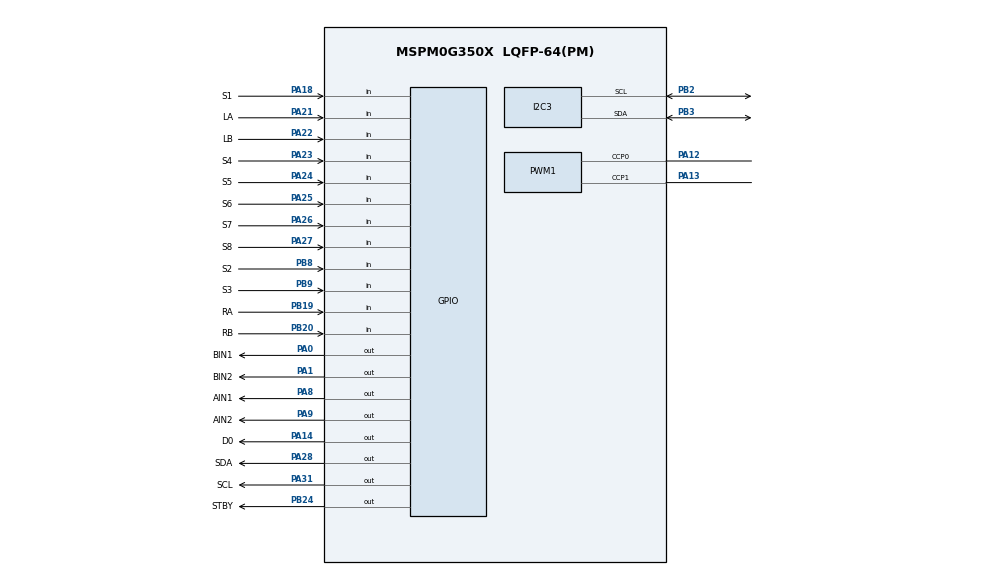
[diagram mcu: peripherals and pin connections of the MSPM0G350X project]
/**
 * @cliArgs --device "MSPM0G350X" --part "Default" --package "LQFP-64(PM)" --product "mspm0_sdk@2.10.00.04"
 * @versions {"tool":"1.26.2+4477"}
 */

/**
 * Import the modules used in this configuration.
 */
const GPIO   = scripting.addModule("/ti/driverlib/GPIO", {}, false);
const GPIO1  = GPIO.addInstance();
const GPIO2  = GPIO.addInstance();
const GPIO3  = GPIO.addInstance();
const GPIO4  = GPIO.addInstance();
const I2C    = scripting.addModule("/ti/driverlib/I2C", {}, false);
const I2C3   = I2C.addInstance();
const PWM    = scripting.addModule("/ti/driverlib/PWM", {}, false);
const PWM1   = PWM.addInstance();
const SYSCTL = scripting.addModule("/ti/driverlib/SYSCTL");
const TIMER  = scripting.addModule("/ti/driverlib/TIMER", {}, false);
const TIMER1 = TIMER.addInstance();

/**
 * Write custom configuration values to the imported modules.
 */
const divider9       = system.clockTree["UDIV"];
divider9.divideValue = 2;

const multiplier2         = system.clockTree["PLL_QDIV"];
multiplier2.multiplyValue = 5;

const mux4       = system.clockTree["EXHFMUX"];
mux4.inputSelect = "EXHFMUX_XTAL";

const mux8       = system.clockTree["HSCLKMUX"];
mux8.inputSelect = "HSCLKMUX_SYSPLL0";

const pinFunction4     = system.clockTree["HFXT"];
pinFunction4.inputFreq = 40;
pinFunction4.enable    = true;

GPIO1.$name                         = "LED";
GPIO1.associatedPins[0].$name       = "D0";
GPIO1.associatedPins[0].pin.$assign = "PA14";

const Board = scripting.addModule("/ti/driverlib/Board", {}, false);

// MPU6050 陀螺仪 (硬件 I2C1, PB2=SCL, PB3=SDA) — 用 OLED 验证过的引脚
I2C3.$name = "MPU6050";
I2C3.basicEnableController = true;
I2C3.peripheral.$assign = "I2C1";
I2C3.peripheral.sdaPin.$assign = "PB3";
I2C3.peripheral.sclPin.$assign = "PB2";
I2C3.sdaPinConfig.internalResistor = "PULL_UP";  // 必须配置上拉！
I2C3.sclPinConfig.internalResistor = "PULL_UP";

// OLED 显示 (软件 I2C, PA28=SDA, PA31=SCL)
GPIO2.$name                          = "OLED_I2C";
GPIO2.associatedPins.create(2);
GPIO2.associatedPins[0].$name        = "SDA";
GPIO2.associatedPins[0].initialValue = "SET";
GPIO2.associatedPins[0].pin.$assign  = "PA28";
GPIO2.associatedPins[1].$name        = "SCL";
GPIO2.associatedPins[1].initialValue = "SET";
GPIO2.associatedPins[1].pin.$assign  = "PA31";

GPIO3.$name                              = "DC_MOTOR";
GPIO3.associatedPins.create(9);
GPIO3.associatedPins[0].$name            = "AIN1";
GPIO3.associatedPins[0].pin.$assign      = "PA8";
GPIO3.associatedPins[1].$name            = "AIN2";
GPIO3.associatedPins[1].pin.$assign      = "PA9";
GPIO3.associatedPins[2].$name            = "BIN1";
GPIO3.associatedPins[2].pin.$assign      = "PA0";
GPIO3.associatedPins[3].$name            = "BIN2";
GPIO3.associatedPins[3].pin.$assign      = "PA1";
GPIO3.associatedPins[4].$name            = "STBY";
GPIO3.associatedPins[4].pin.$assign      = "PB24";
GPIO3.associatedPins[5].$name            = "LA";
GPIO3.associatedPins[5].direction        = "INPUT";
GPIO3.associatedPins[5].interruptEn      = true;
GPIO3.associatedPins[5].polarity         = "RISE";
GPIO3.associatedPins[5].internalResistor = "PULL_DOWN";
GPIO3.associatedPins[5].pin.$assign      = "PA21";
GPIO3.associatedPins[6].$name            = "LB";
GPIO3.associatedPins[6].direction        = "INPUT";
GPIO3.associatedPins[6].internalResistor = "PULL_DOWN";
GPIO3.associatedPins[6].pin.$assign      = "PA22";
GPIO3.associatedPins[7].$name            = "RA";
GPIO3.associatedPins[7].direction        = "INPUT";
GPIO3.associatedPins[7].interruptEn      = true;
GPIO3.associatedPins[7].polarity         = "RISE";
GPIO3.associatedPins[7].internalResistor = "PULL_DOWN";
GPIO3.associatedPins[7].pin.$assign      = "PB19";
GPIO3.associatedPins[8].$name            = "RB";
GPIO3.associatedPins[8].direction        = "INPUT";
GPIO3.associatedPins[8].internalResistor = "PULL_DOWN";
GPIO3.associatedPins[8].pin.$assign      = "PB20";

GPIO4.$name                              = "HUIDU";
GPIO4.associatedPins.create(8);
GPIO4.associatedPins[0].$name            = "S1";
GPIO4.associatedPins[0].direction        = "INPUT";
GPIO4.associatedPins[0].internalResistor = "PULL_UP";
GPIO4.associatedPins[0].pin.$assign      = "PA18";
GPIO4.associatedPins[1].$name            = "S2";
GPIO4.associatedPins[1].direction        = "INPUT";
GPIO4.associatedPins[1].internalResistor = "PULL_UP";
GPIO4.associatedPins[1].pin.$assign      = "PB8";
GPIO4.associatedPins[2].$name            = "S3";
GPIO4.associatedPins[2].direction        = "INPUT";
GPIO4.associatedPins[2].internalResistor = "PULL_UP";
GPIO4.associatedPins[2].pin.$assign      = "PB9";
GPIO4.associatedPins[3].$name            = "S4";
GPIO4.associatedPins[3].direction        = "INPUT";
GPIO4.associatedPins[3].internalResistor = "PULL_UP";
GPIO4.associatedPins[3].pin.$assign      = "PA23";
GPIO4.associatedPins[4].$name            = "S5";
GPIO4.associatedPins[4].direction        = "INPUT";
GPIO4.associatedPins[4].internalResistor = "PULL_UP";
GPIO4.associatedPins[4].pin.$assign      = "PA24";
GPIO4.associatedPins[5].$name            = "S6";
GPIO4.associatedPins[5].direction        = "INPUT";
GPIO4.associatedPins[5].internalResistor = "PULL_UP";
GPIO4.associatedPins[5].pin.$assign      = "PA25";
GPIO4.associatedPins[6].$name            = "S7";
GPIO4.associatedPins[6].direction        = "INPUT";
GPIO4.associatedPins[6].internalResistor = "PULL_UP";
GPIO4.associatedPins[6].pin.$assign      = "PA26";
GPIO4.associatedPins[7].$name            = "S8";
GPIO4.associatedPins[7].direction        = "INPUT";
GPIO4.associatedPins[7].internalResistor = "PULL_UP";
GPIO4.associatedPins[7].pin.$assign      = "PA27";

PWM1.timerStartTimer                    = true;
PWM1.timerCount                         = 4000;
PWM1.pwmMode                            = "EDGE_ALIGN_UP";
PWM1.$name                              = "PWMAB";
PWM1.peripheral.$assign                 = "TIMG0";
PWM1.peripheral.ccp0Pin.$assign         = "PA12";
PWM1.peripheral.ccp1Pin.$assign         = "PA13";
PWM1.PWM_CHANNEL_0.$name                = "ti_driverlib_pwm_PWMTimerCC1";
PWM1.PWM_CHANNEL_1.$name                = "ti_driverlib_pwm_PWMTimerCC2";
PWM1.ccp0PinConfig.$name                = "ti_driverlib_gpio_GPIOPinGeneric2";
PWM1.ccp0PinConfig.direction            = scripting.forceWrite("OUTPUT");
PWM1.ccp0PinConfig.hideOutputInversion  = scripting.forceWrite(false);
PWM1.ccp0PinConfig.onlyInternalResistor = scripting.forceWrite(false);
PWM1.ccp0PinConfig.passedPeripheralType = scripting.forceWrite("Digital");
PWM1.ccp1PinConfig.$name                = "ti_driverlib_gpio_GPIOPinGeneric3";
PWM1.ccp1PinConfig.direction            = scripting.forceWrite("OUTPUT");
PWM1.ccp1PinConfig.hideOutputInversion  = scripting.forceWrite(false);
PWM1.ccp1PinConfig.onlyInternalResistor = scripting.forceWrite(false);
PWM1.ccp1PinConfig.passedPeripheralType = scripting.forceWrite("Digital");

SYSCTL.forceDefaultClkConfig = true;
SYSCTL.clockTreeEn           = true;

TIMER1.$name              = "MOTOR_PID";
TIMER1.timerMode          = "PERIODIC_UP";
TIMER1.timerClkPrescale   = 100;
TIMER1.interrupts         = ["LOAD"];
TIMER1.timerPeriod        = "10ms";
TIMER1.peripheral.$assign = "TIMA0";

/**
 * Pinmux solution for unlocked pins/peripherals. This ensures that minor changes to the automatic solver in a future
 * version of the tool will not impact the pinmux you originally saw.  These lines can be completely deleted in order to
 * re-solve from scratch.
 */
pinFunction4.peripheral.$suggestSolution           = "SYSCTL";
pinFunction4.peripheral.hfxInPin.$suggestSolution  = "PA5";
pinFunction4.peripheral.hfxOutPin.$suggestSolution = "PA6";
Board.peripheral.$suggestSolution                  = "DEBUGSS";
Board.peripheral.swclkPin.$suggestSolution         = "PA20";
Board.peripheral.swdioPin.$suggestSolution         = "PA19";
